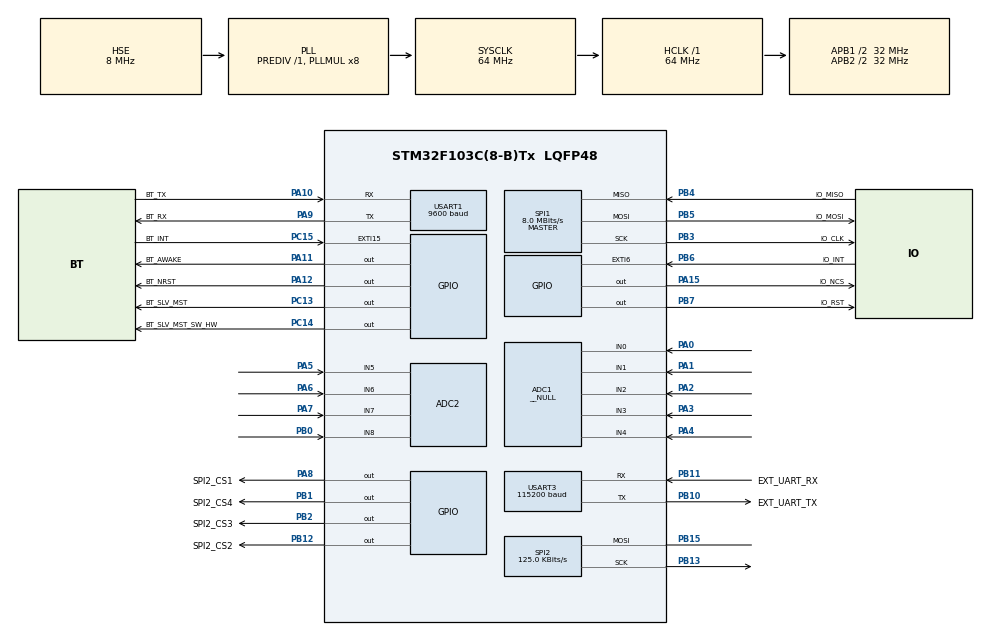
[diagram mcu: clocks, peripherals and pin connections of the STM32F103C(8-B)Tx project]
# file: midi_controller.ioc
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ADC1.Channel-0\#ChannelRegularConversion=ADC_CHANNEL_0
ADC1.Channel-1\#ChannelRegularConversion=ADC_CHANNEL_1
ADC1.Channel-2\#ChannelRegularConversion=ADC_CHANNEL_2
ADC1.Channel-3\#ChannelRegularConversion=ADC_CHANNEL_3
ADC1.Channel-4\#ChannelRegularConversion=ADC_CHANNEL_4
ADC1.ContinuousConvMode=ENABLE
ADC1.DataAlign=ADC_DATAALIGN_RIGHT
ADC1.DiscontinuousConvMode=DISABLE
ADC1.EnableAnalogWatchDog=false
ADC1.EnableRegularConversion=ENABLE
ADC1.ExternalTrigConvEdgeChoice=NONE
ADC1.InjNumberOfConversion=0
ADC1.Mode=__NULL
ADC1.NbrOfConversion=5
ADC1.NbrOfConversionFlag=1
ADC1.Rank-0\#ChannelRegularConversion=1
ADC1.Rank-1\#ChannelRegularConversion=2
ADC1.Rank-2\#ChannelRegularConversion=3
ADC1.Rank-3\#ChannelRegularConversion=4
ADC1.Rank-4\#ChannelRegularConversion=5
ADC1.SamplingTime-0\#ChannelRegularConversion=ADC_SAMPLETIME_239CYCLES_5
ADC1.SamplingTime-1\#ChannelRegularConversion=ADC_SAMPLETIME_239CYCLES_5
ADC1.SamplingTime-2\#ChannelRegularConversion=ADC_SAMPLETIME_239CYCLES_5
ADC1.SamplingTime-3\#ChannelRegularConversion=ADC_SAMPLETIME_239CYCLES_5
ADC1.SamplingTime-4\#ChannelRegularConversion=ADC_SAMPLETIME_239CYCLES_5
ADC1.ScanConvMode=ADC_SCAN_ENABLE
ADC1.master=1
ADC2.Channel-0\#ChannelRegularConversion=ADC_CHANNEL_5
ADC2.NbrOfConversionFlag=1
ADC2.Rank-0\#ChannelRegularConversion=1
ADC2.SamplingTime-0\#ChannelRegularConversion=ADC_SAMPLETIME_1CYCLE_5
Dma.ADC1.4.Direction=DMA_PERIPH_TO_MEMORY
Dma.ADC1.4.Instance=DMA1_Channel1
Dma.ADC1.4.MemDataAlignment=DMA_MDATAALIGN_HALFWORD
Dma.ADC1.4.MemInc=DMA_MINC_ENABLE
Dma.ADC1.4.Mode=DMA_NORMAL
Dma.ADC1.4.PeriphDataAlignment=DMA_PDATAALIGN_HALFWORD
Dma.ADC1.4.PeriphInc=DMA_PINC_DISABLE
Dma.ADC1.4.Priority=DMA_PRIORITY_LOW
Dma.Request0=USART1_TX
Dma.Request1=USART1_RX
Dma.Request2=USART3_RX
Dma.Request3=USART3_TX
Dma.Request4=ADC1
Dma.USART1_RX.1.Direction=DMA_PERIPH_TO_MEMORY
Dma.USART1_RX.1.Instance=DMA1_Channel5
Dma.USART1_RX.1.MemDataAlignment=DMA_MDATAALIGN_BYTE
Dma.USART1_RX.1.MemInc=DMA_MINC_ENABLE
Dma.USART1_RX.1.Mode=DMA_NORMAL
Dma.USART1_RX.1.PeriphDataAlignment=DMA_PDATAALIGN_BYTE
Dma.USART1_RX.1.PeriphInc=DMA_PINC_DISABLE
Dma.USART1_RX.1.Priority=DMA_PRIORITY_MEDIUM
Dma.USART1_TX.0.Direction=DMA_MEMORY_TO_PERIPH
Dma.USART1_TX.0.Instance=DMA1_Channel4
Dma.USART1_TX.0.MemDataAlignment=DMA_MDATAALIGN_BYTE
Dma.USART1_TX.0.MemInc=DMA_MINC_ENABLE
Dma.USART1_TX.0.Mode=DMA_NORMAL
Dma.USART1_TX.0.PeriphDataAlignment=DMA_PDATAALIGN_BYTE
Dma.USART1_TX.0.PeriphInc=DMA_PINC_DISABLE
Dma.USART1_TX.0.Priority=DMA_PRIORITY_MEDIUM
Dma.USART3_RX.2.Direction=DMA_PERIPH_TO_MEMORY
Dma.USART3_RX.2.Instance=DMA1_Channel3
Dma.USART3_RX.2.MemDataAlignment=DMA_MDATAALIGN_BYTE
Dma.USART3_RX.2.MemInc=DMA_MINC_ENABLE
Dma.USART3_RX.2.Mode=DMA_NORMAL
Dma.USART3_RX.2.PeriphDataAlignment=DMA_PDATAALIGN_BYTE
Dma.USART3_RX.2.PeriphInc=DMA_PINC_DISABLE
Dma.USART3_RX.2.Priority=DMA_PRIORITY_MEDIUM
Dma.USART3_TX.3.Direction=DMA_MEMORY_TO_PERIPH
Dma.USART3_TX.3.Instance=DMA1_Channel2
Dma.USART3_TX.3.MemDataAlignment=DMA_MDATAALIGN_BYTE
Dma.USART3_TX.3.MemInc=DMA_MINC_ENABLE
Dma.USART3_TX.3.Mode=DMA_NORMAL
Dma.USART3_TX.3.PeriphDataAlignment=DMA_PDATAALIGN_BYTE
Dma.USART3_TX.3.PeriphInc=DMA_PINC_DISABLE
Dma.USART3_TX.3.Priority=DMA_PRIORITY_MEDIUM
FREERTOS.BinarySemaphores01=BT_tUART_TxIsr;BT_tUART_RxIsr;KB_Pressed;KB_Release;KB_SPI_Busy;ADC1_CNVT_DONE;ADC2_CNVT_DONE
FREERTOS.Queues01=tNoteEventQueue,16,snd_seq_event_t,NULL
FREERTOS.Tasks01=defaultTask,0,256,StartDefaultTask,Default;btCommTask,2,512,BT_Comm,As external;keyboardNoteTas,1,256,KB_NoteRoutine,As external;adc1Task,0,256,ADC1_Routine,As external;adc2Task,-3,256,ADC2_Routine,As external
FREERTOS.configMINIMAL_STACK_SIZE=256
FREERTOS.configTOTAL_HEAP_SIZE=10240
Mcu.Family=STM32F1
Mcu.Name=STM32F103C(8-B)Tx
Mcu.Package=LQFP48
NVIC.DMA1_Channel1_IRQn=true\:10\:0\:true\:false\:true\:true
NVIC.DMA1_Channel2_IRQn=true\:5\:0\:false\:false\:true\:true
NVIC.DMA1_Channel3_IRQn=true\:5\:0\:false\:false\:true\:true
NVIC.DMA1_Channel4_IRQn=true\:10\:0\:true\:false\:true\:true
NVIC.DMA1_Channel5_IRQn=true\:10\:0\:true\:false\:true\:true
NVIC.EXTI9_5_IRQn=true\:7\:0\:true\:false\:true\:true
NVIC.PriorityGroup=NVIC_PRIORITYGROUP_4
NVIC.TIM1_UP_IRQn=true\:0\:0\:false\:false\:true\:false
NVIC.TIM4_IRQn=true\:7\:0\:true\:false\:true\:false
NVIC.TimeBase=TIM1_UP_IRQn
NVIC.TimeBaseIP=TIM1
NVIC.USART1_IRQn=true\:9\:0\:true\:false\:true\:true
NVIC.USART3_IRQn=true\:8\:0\:true\:false\:true\:true
PA0-WKUP.Signal=ADCx_IN0
PA1.Signal=ADCx_IN1
PA10.GPIO_Label=BT_TX
PA10.Mode=Asynchronous
PA10.Signal=USART1_RX
PA11.GPIO_Label=BT_AWAKE
PA11.Signal=GPIO_Output
PA12.GPIO_Label=BT_NRST
PA12.Signal=GPIO_Output
PA13.Mode=Serial_Wire
PA13.Signal=SYS_JTMS-SWDIO
PA14.Mode=Serial_Wire
PA14.Signal=SYS_JTCK-SWCLK
PA15.GPIO_Label=IO_NCS
PA15.Signal=GPIO_Output
PA2.Signal=ADCx_IN2
PA3.Signal=ADCx_IN3
PA4.Signal=ADCx_IN4
PA5.Signal=ADCx_IN5
PA6.Signal=ADCx_IN6
PA7.Signal=ADCx_IN7
PA8.GPIO_Label=SPI2_CS1
PA8.Signal=GPIO_Output
PA9.GPIO_Label=BT_RX
PA9.Mode=Asynchronous
PA9.Signal=USART1_TX
PB0.Signal=ADCx_IN8
PB1.GPIO_Label=SPI2_CS4
PB1.Signal=GPIO_Output
PB10.GPIO_Label=EXT_UART_TX
PB10.Mode=Asynchronous
PB10.Signal=USART3_TX
PB11.GPIO_Label=EXT_UART_RX
PB11.Mode=Asynchronous
PB11.Signal=USART3_RX
PB12.GPIO_Label=SPI2_CS2
PB12.Signal=GPIO_Output
PB13.Mode=Simplex_Bidirectional_Master
PB13.Signal=SPI2_SCK
PB15.Mode=Simplex_Bidirectional_Master
PB15.Signal=SPI2_MOSI
PB2.GPIO_Label=SPI2_CS3
PB2.Signal=GPIO_Output
PB3.GPIO_Label=IO_CLK
PB3.Mode=Full_Duplex_Master
PB3.Signal=SPI1_SCK
PB4.GPIO_Label=IO_MISO
PB4.GPIO_PuPd=GPIO_PULLUP
PB4.Mode=Full_Duplex_Master
PB4.Signal=SPI1_MISO
PB5.GPIO_Label=IO_MOSI
PB5.Mode=Full_Duplex_Master
PB5.Signal=SPI1_MOSI
PB6.GPIO_Label=IO_INT
PB6.GPIO_ModeDefaultEXTI=GPIO_MODE_IT_FALLING
PB6.GPIO_PuPd=GPIO_PULLUP
PB6.Signal=GPXTI6
PB7.GPIO_Label=IO_RST
PB7.Signal=GPIO_Output
PC13-TAMPER-RTC.GPIO_Label=BT_SLV_MST
PC13-TAMPER-RTC.Signal=GPIO_Output
PC14-OSC32_IN.GPIO_Label=BT_SLV_MST_SW_HW
PC14-OSC32_IN.Signal=GPIO_Output
PC15-OSC32_OUT.GPIO_Label=BT_INT
PC15-OSC32_OUT.Signal=GPXTI15
PD0-OSC_IN.Mode=HSE-External-Oscillator
PD0-OSC_IN.Signal=RCC_OSC_IN
PD1-OSC_OUT.Mode=HSE-External-Oscillator
PD1-OSC_OUT.Signal=RCC_OSC_OUT
ProjectManager.HeapSize=0x200
ProjectManager.StackSize=0x400
ProjectManager.TargetToolchain=MDK-ARM V5
RCC.ADCPresc=RCC_ADCPCLK2_DIV8
RCC.AHBFreq_Value=64000000
RCC.APB1CLKDivider=RCC_HCLK_DIV2
RCC.APB1Freq_Value=32000000
RCC.APB1TimFreq_Value=64000000
RCC.APB2CLKDivider=RCC_HCLK_DIV2
RCC.APB2Freq_Value=32000000
RCC.APB2TimFreq_Value=64000000
RCC.HCLKFreq_Value=64000000
RCC.HSIState=RCC_HSI_ON
RCC.PLLMUL=RCC_PLL_MUL8
RCC.PLLSourceVirtual=RCC_PLLSOURCE_HSE
RCC.SYSCLKFreq_VALUE=64000000
RCC.SYSCLKSource=RCC_SYSCLKSOURCE_PLLCLK
RCC.USBFreq_Value=64000000
SH.ADCx_IN0.0=ADC1_IN0,IN0
SH.ADCx_IN1.0=ADC1_IN1,IN1
SH.ADCx_IN2.0=ADC1_IN2,IN2
SH.ADCx_IN3.0=ADC1_IN3,IN3
SH.ADCx_IN4.0=ADC1_IN4,IN4
SH.ADCx_IN5.0=ADC2_IN5,IN5
SH.ADCx_IN6.0=ADC2_IN6,IN6
SH.ADCx_IN7.0=ADC2_IN7,IN7
SH.ADCx_IN8.0=ADC2_IN8,IN8
SPI1.BaudRatePrescaler=SPI_BAUDRATEPRESCALER_4
SPI1.CalculateBaudRate=8.0 MBits/s
SPI1.Mode=SPI_MODE_MASTER
SPI2.BaudRatePrescaler=SPI_BAUDRATEPRESCALER_256
SPI2.CalculateBaudRate=125.0 KBits/s
SPI2.Direction=SPI_DIRECTION_1LINE
SPI2.Mode=SPI_MODE_MASTER
TIM4.Prescaler=63
USART1.BaudRate=9600
USART3.BaudRate=115200
USART3.Parity=UART_PARITY_ODD
USART3.WordLength=UART_WORDLENGTH_9B
VP_FREERTOS_VS_ENABLE.Mode=Enabled
VP_SYS_VS_tim1.Mode=TIM1
VP_TIM4_VS_ClockSourceINT.Mode=Internal
board=midi_controller

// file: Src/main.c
/**
  ******************************************************************************
  * File Name          : main.c
  * Description        : Main program body
  ******************************************************************************
  *
  * COPYRIGHT(c) 2016 STMicroelectronics
  *
  * Redistribution and use in source and binary forms, with or without modification,
  * are permitted provided that the following conditions are met:
  *   1. Redistributions of source code must retain the above copyright notice,
  *      this list of conditions and the following disclaimer.
  *   2. Redistributions in binary form must reproduce the above copyright notice,
  *      this list of conditions and the following disclaimer in the documentation
  *      and/or other materials provided with the distribution.
  *   3. Neither the name of STMicroelectronics nor the names of its contributors
  *      may be used to endorse or promote products derived from this software
  *      without specific prior written permission.
  *
  * THIS SOFTWARE IS PROVIDED BY THE COPYRIGHT HOLDERS AND CONTRIBUTORS "AS IS"
  * AND ANY EXPRESS OR IMPLIED WARRANTIES, INCLUDING, BUT NOT LIMITED TO, THE
  * IMPLIED WARRANTIES OF MERCHANTABILITY AND FITNESS FOR A PARTICULAR PURPOSE ARE
  * DISCLAIMED. IN NO EVENT SHALL THE COPYRIGHT HOLDER OR CONTRIBUTORS BE LIABLE
  * FOR ANY DIRECT, INDIRECT, INCIDENTAL, SPECIAL, EXEMPLARY, OR CONSEQUENTIAL
  * DAMAGES (INCLUDING, BUT NOT LIMITED TO, PROCUREMENT OF SUBSTITUTE GOODS OR
  * SERVICES; LOSS OF USE, DATA, OR PROFITS; OR BUSINESS INTERRUPTION) HOWEVER
  * CAUSED AND ON ANY THEORY OF LIABILITY, WHETHER IN CONTRACT, STRICT LIABILITY,
  * OR TORT (INCLUDING NEGLIGENCE OR OTHERWISE) ARISING IN ANY WAY OUT OF THE USE
  * OF THIS SOFTWARE, EVEN IF ADVISED OF THE POSSIBILITY OF SUCH DAMAGE.
  *
  ******************************************************************************
  */
#include "stm32f1xx_hal.h"
#include "cmsis_os.h"

/* USER CODE BEGIN Includes */
#include "seq_event.h"
#include "global.h"
/* USER CODE END Includes */

ADC_HandleTypeDef hadc1;
ADC_HandleTypeDef hadc2;
DMA_HandleTypeDef hdma_adc1;

SPI_HandleTypeDef hspi1;
SPI_HandleTypeDef hspi2;

TIM_HandleTypeDef htim4;

UART_HandleTypeDef huart1;
UART_HandleTypeDef huart3;
DMA_HandleTypeDef hdma_usart1_tx;
DMA_HandleTypeDef hdma_usart1_rx;
DMA_HandleTypeDef hdma_usart3_rx;
DMA_HandleTypeDef hdma_usart3_tx;

osThreadId defaultTaskHandle;
osThreadId btCommTaskHandle;
osThreadId keyboardNoteTasHandle;
osThreadId adc1TaskHandle;
osThreadId adc2TaskHandle;
osMessageQId tNoteEventQueueHandle;
osSemaphoreId BT_tUART_TxIsrHandle;
osSemaphoreId BT_tUART_RxIsrHandle;
osSemaphoreId KB_PressedHandle;
osSemaphoreId KB_ReleaseHandle;
osSemaphoreId KB_SPI_BusyHandle;
osSemaphoreId ADC1_CNVT_DONEHandle;
osSemaphoreId ADC2_CNVT_DONEHandle;

/* USER CODE BEGIN PV */
/* Private variables ---------------------------------------------------------*/

/* USER CODE END PV */

void SystemClock_Config(void);
void Error_Handler(void);
static void MX_GPIO_Init(void);
static void MX_DMA_Init(void);
static void MX_ADC1_Init(void);
static void MX_SPI1_Init(void);
static void MX_SPI2_Init(void);
static void MX_USART1_UART_Init(void);
static void MX_USART3_UART_Init(void);
static void MX_TIM4_Init(void);
static void MX_ADC2_Init(void);
void StartDefaultTask(void const * argument);
extern void BT_Comm(void const * argument);
extern void KB_NoteRoutine(void const * argument);
extern void ADC1_Routine(void const * argument);
extern void ADC2_Routine(void const * argument);

/* USER CODE BEGIN PFP */
/* Private function prototypes -----------------------------------------------*/

/* USER CODE END PFP */

/* USER CODE BEGIN 0 */
uint8_t unVelocity[MIDI_MAX_CHANNEL];
/* USER CODE END 0 */

int main(void)
{

  /* MCU Configuration----------------------------------------------------------*/

  /* Reset of all peripherals, Initializes the Flash interface and the Systick. */
  HAL_Init();

  /* Configure the system clock */
  SystemClock_Config();

  /* Initialize all configured peripherals */
  MX_GPIO_Init();
  MX_DMA_Init();
  MX_ADC1_Init();
  MX_SPI1_Init();
  MX_SPI2_Init();
  MX_USART1_UART_Init();
  MX_USART3_UART_Init();
  MX_TIM4_Init();
  MX_ADC2_Init();

  /* Create the semaphores(s) */
  /* definition and creation of BT_tUART_TxIsr */
  osSemaphoreDef(BT_tUART_TxIsr);
  BT_tUART_TxIsrHandle = osSemaphoreCreate(osSemaphore(BT_tUART_TxIsr), 1);

  /* definition and creation of BT_tUART_RxIsr */
  osSemaphoreDef(BT_tUART_RxIsr);
  BT_tUART_RxIsrHandle = osSemaphoreCreate(osSemaphore(BT_tUART_RxIsr), 1);

  /* definition and creation of KB_Pressed */
  osSemaphoreDef(KB_Pressed);
  KB_PressedHandle = osSemaphoreCreate(osSemaphore(KB_Pressed), 1);

  /* definition and creation of KB_Release */
  osSemaphoreDef(KB_Release);
  KB_ReleaseHandle = osSemaphoreCreate(osSemaphore(KB_Release), 1);

  /* definition and creation of KB_SPI_Busy */
  osSemaphoreDef(KB_SPI_Busy);
  KB_SPI_BusyHandle = osSemaphoreCreate(osSemaphore(KB_SPI_Busy), 1);

  /* definition and creation of ADC1_CNVT_DONE */
  osSemaphoreDef(ADC1_CNVT_DONE);
  ADC1_CNVT_DONEHandle = osSemaphoreCreate(osSemaphore(ADC1_CNVT_DONE), 1);

  /* definition and creation of ADC2_CNVT_DONE */
  osSemaphoreDef(ADC2_CNVT_DONE);
  ADC2_CNVT_DONEHandle = osSemaphoreCreate(osSemaphore(ADC2_CNVT_DONE), 1);

  /* Create the thread(s) */
  /* definition and creation of defaultTask */
  osThreadDef(defaultTask, StartDefaultTask, osPriorityNormal, 0, 256);
  defaultTaskHandle = osThreadCreate(osThread(defaultTask), NULL);

  /* definition and creation of btCommTask */
  osThreadDef(btCommTask, BT_Comm, osPriorityHigh, 0, 512);
  btCommTaskHandle = osThreadCreate(osThread(btCommTask), NULL);

  /* definition and creation of keyboardNoteTas */
  osThreadDef(keyboardNoteTas, KB_NoteRoutine, osPriorityAboveNormal, 0, 256);
  keyboardNoteTasHandle = osThreadCreate(osThread(keyboardNoteTas), NULL);

  /* definition and creation of adc1Task */
  osThreadDef(adc1Task, ADC1_Routine, osPriorityNormal, 0, 256);
  adc1TaskHandle = osThreadCreate(osThread(adc1Task), NULL);

  /* definition and creation of adc2Task */
  osThreadDef(adc2Task, ADC2_Routine, osPriorityIdle, 0, 256);
  adc2TaskHandle = osThreadCreate(osThread(adc2Task), NULL);

  /* Create the queue(s) */
  /* definition and creation of tNoteEventQueue */
  osMessageQDef(tNoteEventQueue, 16, snd_seq_event_t);
  tNoteEventQueueHandle = osMessageCreate(osMessageQ(tNoteEventQueue), NULL);

  /* Start scheduler */
  osKernelStart();

  /* We should never get here as control is now taken by the scheduler */

  /* Infinite loop */
  while (1)
  {

  }

}

/** System Clock Configuration
*/
void SystemClock_Config(void)
{

  RCC_OscInitTypeDef RCC_OscInitStruct;
  RCC_ClkInitTypeDef RCC_ClkInitStruct;
  RCC_PeriphCLKInitTypeDef PeriphClkInit;

  RCC_OscInitStruct.OscillatorType = RCC_OSCILLATORTYPE_HSE;
  RCC_OscInitStruct.HSEState = RCC_HSE_ON;
  RCC_OscInitStruct.HSEPredivValue = RCC_HSE_PREDIV_DIV1;
  RCC_OscInitStruct.PLL.PLLState = RCC_PLL_ON;
  RCC_OscInitStruct.PLL.PLLSource = RCC_PLLSOURCE_HSE;
  RCC_OscInitStruct.PLL.PLLMUL = RCC_PLL_MUL8;
  if (HAL_RCC_OscConfig(&RCC_OscInitStruct) != HAL_OK)
  {
    Error_Handler();
  }

  RCC_ClkInitStruct.ClockType = RCC_CLOCKTYPE_HCLK|RCC_CLOCKTYPE_SYSCLK
                              |RCC_CLOCKTYPE_PCLK1|RCC_CLOCKTYPE_PCLK2;
  RCC_ClkInitStruct.SYSCLKSource = RCC_SYSCLKSOURCE_PLLCLK;
  RCC_ClkInitStruct.AHBCLKDivider = RCC_SYSCLK_DIV1;
  RCC_ClkInitStruct.APB1CLKDivider = RCC_HCLK_DIV2;
  RCC_ClkInitStruct.APB2CLKDivider = RCC_HCLK_DIV2;
  if (HAL_RCC_ClockConfig(&RCC_ClkInitStruct, FLASH_LATENCY_2) != HAL_OK)
  {
    Error_Handler();
  }

  PeriphClkInit.PeriphClockSelection = RCC_PERIPHCLK_ADC;
  PeriphClkInit.AdcClockSelection = RCC_ADCPCLK2_DIV8;
  if (HAL_RCCEx_PeriphCLKConfig(&PeriphClkInit) != HAL_OK)
  {
    Error_Handler();
  }

  HAL_SYSTICK_Config(HAL_RCC_GetHCLKFreq()/1000);

  HAL_SYSTICK_CLKSourceConfig(SYSTICK_CLKSOURCE_HCLK);

  /* SysTick_IRQn interrupt configuration */
  HAL_NVIC_SetPriority(SysTick_IRQn, 15, 0);
}

/* ADC1 init function */
static void MX_ADC1_Init(void)
{

  ADC_ChannelConfTypeDef sConfig;

    /**Common config
    */
  hadc1.Instance = ADC1;
  hadc1.Init.ScanConvMode = ADC_SCAN_ENABLE;
  hadc1.Init.ContinuousConvMode = ENABLE;
  hadc1.Init.DiscontinuousConvMode = DISABLE;
  hadc1.Init.ExternalTrigConv = ADC_SOFTWARE_START;
  hadc1.Init.DataAlign = ADC_DATAALIGN_RIGHT;
  hadc1.Init.NbrOfConversion = 5;
  if (HAL_ADC_Init(&hadc1) != HAL_OK)
  {
    Error_Handler();
  }

    /**Configure Regular Channel
    */
  sConfig.Channel = ADC_CHANNEL_0;
  sConfig.Rank = 1;
  sConfig.SamplingTime = ADC_SAMPLETIME_239CYCLES_5;
  if (HAL_ADC_ConfigChannel(&hadc1, &sConfig) != HAL_OK)
  {
    Error_Handler();
  }

    /**Configure Regular Channel
    */
  sConfig.Channel = ADC_CHANNEL_1;
  sConfig.Rank = 2;
  if (HAL_ADC_ConfigChannel(&hadc1, &sConfig) != HAL_OK)
  {
    Error_Handler();
  }

    /**Configure Regular Channel
    */
  sConfig.Channel = ADC_CHANNEL_2;
  sConfig.Rank = 3;
  if (HAL_ADC_ConfigChannel(&hadc1, &sConfig) != HAL_OK)
  {
    Error_Handler();
  }

    /**Configure Regular Channel
    */
  sConfig.Channel = ADC_CHANNEL_3;
  sConfig.Rank = 4;
  if (HAL_ADC_ConfigChannel(&hadc1, &sConfig) != HAL_OK)
  {
    Error_Handler();
  }

    /**Configure Regular Channel
    */
  sConfig.Channel = ADC_CHANNEL_4;
  sConfig.Rank = 5;
  if (HAL_ADC_ConfigChannel(&hadc1, &sConfig) != HAL_OK)
  {
    Error_Handler();
  }

}

/* ADC2 init function */
static void MX_ADC2_Init(void)
{

  ADC_ChannelConfTypeDef sConfig;

    /**Common config
    */
  hadc2.Instance = ADC2;
  hadc2.Init.ScanConvMode = ADC_SCAN_DISABLE;
  hadc2.Init.ContinuousConvMode = DISABLE;
  hadc2.Init.DiscontinuousConvMode = DISABLE;
  hadc2.Init.ExternalTrigConv = ADC_SOFTWARE_START;
  hadc2.Init.DataAlign = ADC_DATAALIGN_RIGHT;
  hadc2.Init.NbrOfConversion = 1;
  if (HAL_ADC_Init(&hadc2) != HAL_OK)
  {
    Error_Handler();
  }

    /**Configure Regular Channel
    */
  sConfig.Channel = ADC_CHANNEL_5;
  sConfig.Rank = 1;
  sConfig.SamplingTime = ADC_SAMPLETIME_1CYCLE_5;
  if (HAL_ADC_ConfigChannel(&hadc2, &sConfig) != HAL_OK)
  {
    Error_Handler();
  }

}

/* SPI1 init function */
static void MX_SPI1_Init(void)
{

  hspi1.Instance = SPI1;
  hspi1.Init.Mode = SPI_MODE_MASTER;
  hspi1.Init.Direction = SPI_DIRECTION_2LINES;
  hspi1.Init.DataSize = SPI_DATASIZE_8BIT;
  hspi1.Init.CLKPolarity = SPI_POLARITY_LOW;
  hspi1.Init.CLKPhase = SPI_PHASE_1EDGE;
  hspi1.Init.NSS = SPI_NSS_SOFT;
  hspi1.Init.BaudRatePrescaler = SPI_BAUDRATEPRESCALER_4;
  hspi1.Init.FirstBit = SPI_FIRSTBIT_MSB;
  hspi1.Init.TIMode = SPI_TIMODE_DISABLE;
  hspi1.Init.CRCCalculation = SPI_CRCCALCULATION_DISABLE;
  hspi1.Init.CRCPolynomial = 10;
  if (HAL_SPI_Init(&hspi1) != HAL_OK)
  {
    Error_Handler();
  }

}

/* SPI2 init function */
static void MX_SPI2_Init(void)
{

  hspi2.Instance = SPI2;
  hspi2.Init.Mode = SPI_MODE_MASTER;
  hspi2.Init.Direction = SPI_DIRECTION_1LINE;
  hspi2.Init.DataSize = SPI_DATASIZE_8BIT;
  hspi2.Init.CLKPolarity = SPI_POLARITY_LOW;
  hspi2.Init.CLKPhase = SPI_PHASE_1EDGE;
  hspi2.Init.NSS = SPI_NSS_SOFT;
  hspi2.Init.BaudRatePrescaler = SPI_BAUDRATEPRESCALER_256;
  hspi2.Init.FirstBit = SPI_FIRSTBIT_MSB;
  hspi2.Init.TIMode = SPI_TIMODE_DISABLE;
  hspi2.Init.CRCCalculation = SPI_CRCCALCULATION_DISABLE;
  hspi2.Init.CRCPolynomial = 10;
  if (HAL_SPI_Init(&hspi2) != HAL_OK)
  {
    Error_Handler();
  }

}

/* TIM4 init function */
static void MX_TIM4_Init(void)
{

  TIM_ClockConfigTypeDef sClockSourceConfig;
  TIM_MasterConfigTypeDef sMasterConfig;

  htim4.Instance = TIM4;
  htim4.Init.Prescaler = 63;
  htim4.Init.CounterMode = TIM_COUNTERMODE_UP;
  htim4.Init.Period = 0;
  htim4.Init.ClockDivision = TIM_CLOCKDIVISION_DIV1;
  if (HAL_TIM_Base_Init(&htim4) != HAL_OK)
  {
    Error_Handler();
  }

  sClockSourceConfig.ClockSource = TIM_CLOCKSOURCE_INTERNAL;
  if (HAL_TIM_ConfigClockSource(&htim4, &sClockSourceConfig) != HAL_OK)
  {
    Error_Handler();
  }

  sMasterConfig.MasterOutputTrigger = TIM_TRGO_RESET;
  sMasterConfig.MasterSlaveMode = TIM_MASTERSLAVEMODE_DISABLE;
  if (HAL_TIMEx_MasterConfigSynchronization(&htim4, &sMasterConfig) != HAL_OK)
  {
    Error_Handler();
  }

}

/* USART1 init function */
static void MX_USART1_UART_Init(void)
{

  huart1.Instance = USART1;
  huart1.Init.BaudRate = 9600;
  huart1.Init.WordLength = UART_WORDLENGTH_8B;
  huart1.Init.StopBits = UART_STOPBITS_1;
  huart1.Init.Parity = UART_PARITY_NONE;
  huart1.Init.Mode = UART_MODE_TX_RX;
  huart1.Init.HwFlowCtl = UART_HWCONTROL_NONE;
  huart1.Init.OverSampling = UART_OVERSAMPLING_16;
  if (HAL_UART_Init(&huart1) != HAL_OK)
  {
    Error_Handler();
  }

}

/* USART3 init function */
static void MX_USART3_UART_Init(void)
{

  huart3.Instance = USART3;
  huart3.Init.BaudRate = 115200;
  huart3.Init.WordLength = UART_WORDLENGTH_9B;
  huart3.Init.StopBits = UART_STOPBITS_1;
  huart3.Init.Parity = UART_PARITY_ODD;
  huart3.Init.Mode = UART_MODE_TX_RX;
  huart3.Init.HwFlowCtl = UART_HWCONTROL_NONE;
  huart3.Init.OverSampling = UART_OVERSAMPLING_16;
  if (HAL_UART_Init(&huart3) != HAL_OK)
  {
    Error_Handler();
  }

}

static void MX_DMA_Init(void)
{
  /* DMA controller clock enable */
  __HAL_RCC_DMA1_CLK_ENABLE();

  /* DMA interrupt init */
  /* DMA1_Channel1_IRQn interrupt configuration */
  HAL_NVIC_SetPriority(DMA1_Channel1_IRQn, 10, 0);
  HAL_NVIC_EnableIRQ(DMA1_Channel1_IRQn);
  /* DMA1_Channel2_IRQn interrupt configuration */
  HAL_NVIC_SetPriority(DMA1_Channel2_IRQn, 5, 0);
  HAL_NVIC_EnableIRQ(DMA1_Channel2_IRQn);
  /* DMA1_Channel3_IRQn interrupt configuration */
  HAL_NVIC_SetPriority(DMA1_Channel3_IRQn, 5, 0);
  HAL_NVIC_EnableIRQ(DMA1_Channel3_IRQn);
  /* DMA1_Channel4_IRQn interrupt configuration */
  HAL_NVIC_SetPriority(DMA1_Channel4_IRQn, 10, 0);
  HAL_NVIC_EnableIRQ(DMA1_Channel4_IRQn);
  /* DMA1_Channel5_IRQn interrupt configuration */
  HAL_NVIC_SetPriority(DMA1_Channel5_IRQn, 10, 0);
  HAL_NVIC_EnableIRQ(DMA1_Channel5_IRQn);

}

/** Configure pins as
        * Analog
        * Input
        * Output
        * EVENT_OUT
        * EXTI
*/
static void MX_GPIO_Init(void)
{

  GPIO_InitTypeDef GPIO_InitStruct;

  /* GPIO Ports Clock Enable */
  __HAL_RCC_GPIOC_CLK_ENABLE();
  __HAL_RCC_GPIOD_CLK_ENABLE();
  __HAL_RCC_GPIOA_CLK_ENABLE();
  __HAL_RCC_GPIOB_CLK_ENABLE();

  /*Configure GPIO pin Output Level */
  HAL_GPIO_WritePin(GPIOC, BT_SLV_MST_Pin|BT_SLV_MST_SW_HW_Pin, GPIO_PIN_RESET);

  /*Configure GPIO pin Output Level */
  HAL_GPIO_WritePin(GPIOB, SPI2_CS4_Pin|SPI2_CS3_Pin|SPI2_CS2_Pin|IO_RST_Pin, GPIO_PIN_RESET);

  /*Configure GPIO pin Output Level */
  HAL_GPIO_WritePin(GPIOA, SPI2_CS1_Pin|BT_AWAKE_Pin|BT_NRST_Pin|IO_NCS_Pin, GPIO_PIN_RESET);

  /*Configure GPIO pins : BT_SLV_MST_Pin BT_SLV_MST_SW_HW_Pin */
  GPIO_InitStruct.Pin = BT_SLV_MST_Pin|BT_SLV_MST_SW_HW_Pin;
  GPIO_InitStruct.Mode = GPIO_MODE_OUTPUT_PP;
  GPIO_InitStruct.Speed = GPIO_SPEED_FREQ_LOW;
  HAL_GPIO_Init(GPIOC, &GPIO_InitStruct);

  /*Configure GPIO pin : BT_INT_Pin */
  GPIO_InitStruct.Pin = BT_INT_Pin;
  GPIO_InitStruct.Mode = GPIO_MODE_IT_RISING;
  GPIO_InitStruct.Pull = GPIO_NOPULL;
  HAL_GPIO_Init(BT_INT_GPIO_Port, &GPIO_InitStruct);

  /*Configure GPIO pins : SPI2_CS4_Pin SPI2_CS3_Pin SPI2_CS2_Pin IO_RST_Pin */
  GPIO_InitStruct.Pin = SPI2_CS4_Pin|SPI2_CS3_Pin|SPI2_CS2_Pin|IO_RST_Pin;
  GPIO_InitStruct.Mode = GPIO_MODE_OUTPUT_PP;
  GPIO_InitStruct.Speed = GPIO_SPEED_FREQ_LOW;
  HAL_GPIO_Init(GPIOB, &GPIO_InitStruct);

  /*Configure GPIO pins : SPI2_CS1_Pin BT_AWAKE_Pin BT_NRST_Pin IO_NCS_Pin */
  GPIO_InitStruct.Pin = SPI2_CS1_Pin|BT_AWAKE_Pin|BT_NRST_Pin|IO_NCS_Pin;
  GPIO_InitStruct.Mode = GPIO_MODE_OUTPUT_PP;
  GPIO_InitStruct.Speed = GPIO_SPEED_FREQ_LOW;
  HAL_GPIO_Init(GPIOA, &GPIO_InitStruct);

  /*Configure GPIO pin : IO_INT_Pin */
  GPIO_InitStruct.Pin = IO_INT_Pin;
  GPIO_InitStruct.Mode = GPIO_MODE_IT_FALLING;
  GPIO_InitStruct.Pull = GPIO_PULLUP;
  HAL_GPIO_Init(IO_INT_GPIO_Port, &GPIO_InitStruct);

  /* EXTI interrupt init*/
  HAL_NVIC_SetPriority(EXTI9_5_IRQn, 7, 0);
  HAL_NVIC_EnableIRQ(EXTI9_5_IRQn);

}

/* StartDefaultTask function */
void StartDefaultTask(void const * argument)
{

  for(;;)
  {
    osDelay(1);
  }
}

void HAL_TIM_PeriodElapsedCallback(TIM_HandleTypeDef *htim)
{
  if (htim->Instance == TIM1) {
    HAL_IncTick();
  }
/* USER CODE BEGIN Callback 1 */
  if (htim->Instance == TIM4) {
		HAL_TIM_Base_Stop_IT(&htim4);
    osSemaphoreRelease(KB_SPI_BusyHandle);
  }
/* USER CODE END Callback 1 */
}

void Error_Handler(void)
{
  while(1)
  {
  }
}

/************************ (C) COPYRIGHT STMicroelectronics *****END OF FILE****/
